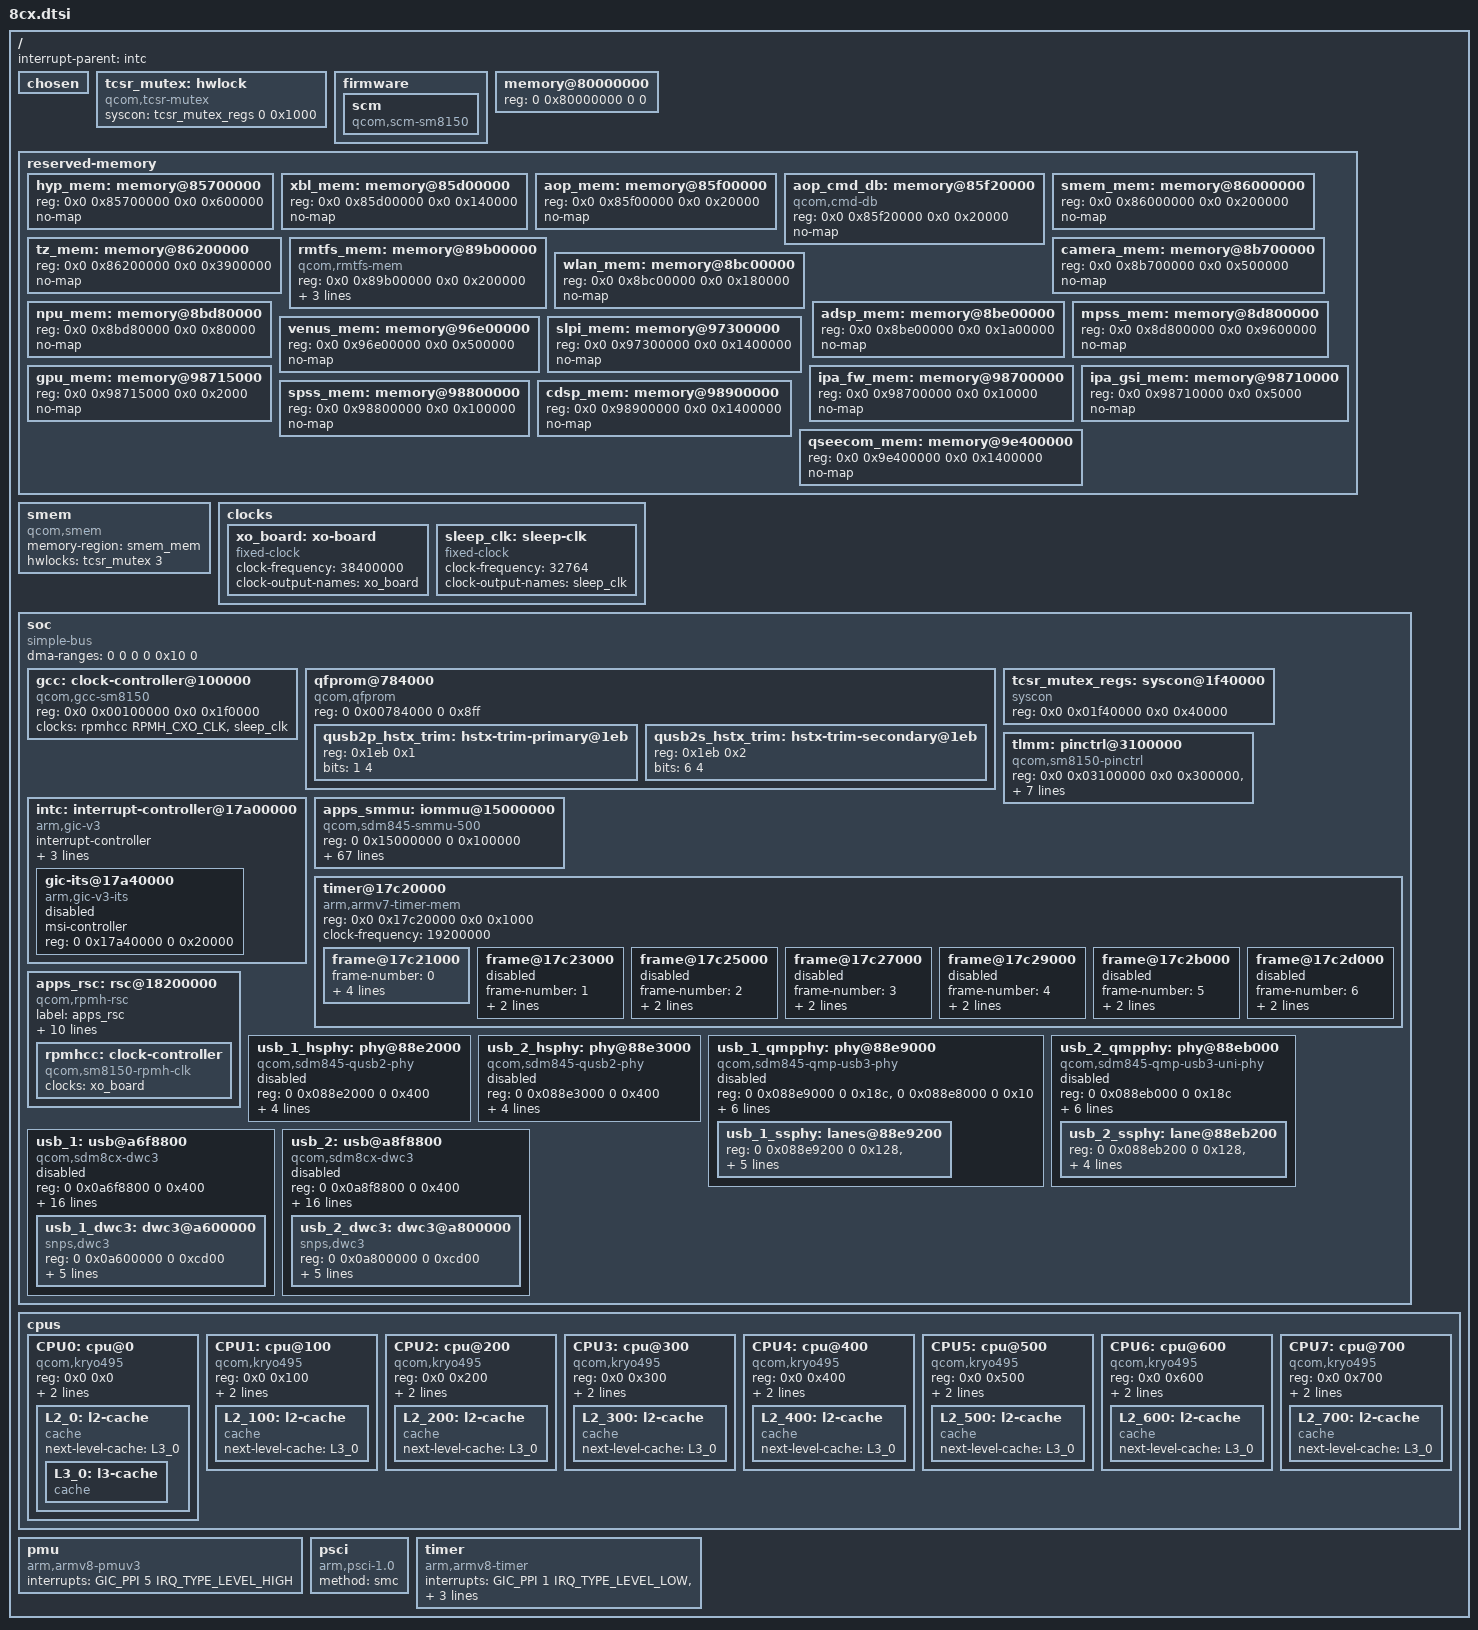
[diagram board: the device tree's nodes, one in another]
// SPDX-License-Identifier: BSD-3-Clause

#include <dt-bindings/clock/qcom,gcc-sdm845.h>
#include <dt-bindings/interrupt-controller/arm-gic.h>
#include <dt-bindings/phy/phy-qcom-qusb2.h>
#include <dt-bindings/soc/qcom,rpmh-rsc.h>
#include <dt-bindings/clock/qcom,rpmh.h>

/ {
	interrupt-parent = <&intc>;

	#address-cells = <2>;
	#size-cells = <2>;

	chosen { };

	tcsr_mutex: hwlock {
		compatible = "qcom,tcsr-mutex";
		syscon = <&tcsr_mutex_regs 0 0x1000>;
		#hwlock-cells = <1>;
	};

	firmware {
		scm: scm {
			compatible = "qcom,scm-sm8150", "qcom,scm";
			#reset-cells = <1>;
		};
	};

	memory@80000000 {
		device_type = "memory";
		/* We expect the bootloader to fill in the size */
		reg = <0 0x80000000 0 0>;
	};

	reserved-memory {
		#address-cells = <2>;
		#size-cells = <2>;
		ranges;

		hyp_mem: memory@85700000 {
			reg = <0x0 0x85700000 0x0 0x600000>;
			no-map;
		};

		xbl_mem: memory@85d00000 {
			reg = <0x0 0x85d00000 0x0 0x140000>;
			no-map;
		};

		aop_mem: memory@85f00000 {
			reg = <0x0 0x85f00000 0x0 0x20000>;
			no-map;
		};

		aop_cmd_db: memory@85f20000 {
			compatible = "qcom,cmd-db";
			reg = <0x0 0x85f20000 0x0 0x20000>;
			no-map;
		};

		smem_mem: memory@86000000 {
			reg = <0x0 0x86000000 0x0 0x200000>;
			no-map;
		};

		tz_mem: memory@86200000 {
			reg = <0x0 0x86200000 0x0 0x3900000>;
			no-map;
		};

		rmtfs_mem: memory@89b00000 {
			compatible = "qcom,rmtfs-mem";
			reg = <0x0 0x89b00000 0x0 0x200000>;
			no-map;

			qcom,client-id = <1>;
			qcom,vmid = <15>;
		};

		camera_mem: memory@8b700000 {
			reg = <0x0 0x8b700000 0x0 0x500000>;
			no-map;
		};

		wlan_mem: memory@8bc00000 {
			reg = <0x0 0x8bc00000 0x0 0x180000>;
			no-map;
		};

		npu_mem: memory@8bd80000 {
			reg = <0x0 0x8bd80000 0x0 0x80000>;
			no-map;
		};

		adsp_mem: memory@8be00000 {
			reg = <0x0 0x8be00000 0x0 0x1a00000>;
			no-map;
		};

		mpss_mem: memory@8d800000 {
			reg = <0x0 0x8d800000 0x0 0x9600000>;
			no-map;
		};

		venus_mem: memory@96e00000 {
			reg = <0x0 0x96e00000 0x0 0x500000>;
			no-map;
		};

		slpi_mem: memory@97300000 {
			reg = <0x0 0x97300000 0x0 0x1400000>;
			no-map;
		};

		ipa_fw_mem: memory@98700000 {
			reg = <0x0 0x98700000 0x0 0x10000>;
			no-map;
		};

		ipa_gsi_mem: memory@98710000 {
			reg = <0x0 0x98710000 0x0 0x5000>;
			no-map;
		};

		gpu_mem: memory@98715000 {
			reg = <0x0 0x98715000 0x0 0x2000>;
			no-map;
		};

		spss_mem: memory@98800000 {
			reg = <0x0 0x98800000 0x0 0x100000>;
			no-map;
		};

		cdsp_mem: memory@98900000 {
			reg = <0x0 0x98900000 0x0 0x1400000>;
			no-map;
		};

		qseecom_mem: memory@9e400000 {
			reg = <0x0 0x9e400000 0x0 0x1400000>;
			no-map;
		};
	};

	smem {
		compatible = "qcom,smem";
		memory-region = <&smem_mem>;
		hwlocks = <&tcsr_mutex 3>;
	};


	clocks {
		xo_board: xo-board {
			compatible = "fixed-clock";
			#clock-cells = <0>;
			clock-frequency = <38400000>;
			clock-output-names = "xo_board";
		};

		sleep_clk: sleep-clk {
			compatible = "fixed-clock";
			#clock-cells = <0>;
			clock-frequency = <32764>;
			clock-output-names = "sleep_clk";
		};
	};

	soc: soc {
		#address-cells = <2>;
		#size-cells = <2>;
		ranges = <0 0 0 0 0x10 0>;
		dma-ranges = <0 0 0 0 0x10 0>;
		compatible = "simple-bus";

		gcc: clock-controller@100000 {
			compatible = "qcom,gcc-sm8150";
			reg = <0x0 0x00100000 0x0 0x1f0000>;
			#clock-cells = <1>;
			#reset-cells = <1>;
			#power-domain-cells = <1>;
			clock-names = "bi_tcxo",
				      "sleep_clk";
			clocks = <&rpmhcc RPMH_CXO_CLK>,
				 <&sleep_clk>;
		};

		qfprom@784000 {
			compatible = "qcom,qfprom";
			reg = <0 0x00784000 0 0x8ff>;
			#address-cells = <1>;
			#size-cells = <1>;

			qusb2p_hstx_trim: hstx-trim-primary@1eb {
				reg = <0x1eb 0x1>;
				bits = <1 4>;
			};

			qusb2s_hstx_trim: hstx-trim-secondary@1eb {
				reg = <0x1eb 0x2>;
				bits = <6 4>;
			};
		};


		tcsr_mutex_regs: syscon@1f40000 {
			compatible = "syscon";
			reg = <0x0 0x01f40000 0x0 0x40000>;
		};

		tlmm: pinctrl@3100000 {
			compatible = "qcom,sm8150-pinctrl";
			reg = <0x0 0x03100000 0x0 0x300000>,
			      <0x0 0x03500000 0x0 0x300000>,
			      <0x0 0x03900000 0x0 0x300000>,
			      <0x0 0x03D00000 0x0 0x300000>;
			reg-names = "west", "east", "north", "south";
			interrupts = <GIC_SPI 208 IRQ_TYPE_LEVEL_HIGH>;
			gpio-ranges = <&tlmm 0 0 175>;
			gpio-controller;
			#gpio-cells = <2>;
			interrupt-controller;
			#interrupt-cells = <2>;
		};

		intc: interrupt-controller@17a00000 {
			compatible = "arm,gic-v3";
			#address-cells = <2>;
			#size-cells = <2>;
			ranges;
			#interrupt-cells = <3>;
			interrupt-controller;
			reg = <0 0x17a00000 0 0x10000>,     /* GICD */
			      <0 0x17a60000 0 0x100000>;    /* GICR * 8 */
			interrupts = <GIC_PPI 9 IRQ_TYPE_LEVEL_HIGH>;

			gic-its@17a40000 {
				compatible = "arm,gic-v3-its";
				msi-controller;
				#msi-cells = <1>;
				reg = <0 0x17a40000 0 0x20000>;
				status = "disabled";
			};
		};

		apps_smmu: iommu@15000000 {
			compatible = "qcom,sdm845-smmu-500", "arm,mmu-500";
			reg = <0 0x15000000 0 0x100000>;
			#iommu-cells = <2>;
			#global-interrupts = <1>;
			interrupts = <GIC_SPI 65 IRQ_TYPE_LEVEL_HIGH>,
				     <GIC_SPI 96 IRQ_TYPE_LEVEL_HIGH>,
				     <GIC_SPI 97 IRQ_TYPE_LEVEL_HIGH>,
				     <GIC_SPI 98 IRQ_TYPE_LEVEL_HIGH>,
				     <GIC_SPI 99 IRQ_TYPE_LEVEL_HIGH>,
				     <GIC_SPI 100 IRQ_TYPE_LEVEL_HIGH>,
				     <GIC_SPI 101 IRQ_TYPE_LEVEL_HIGH>,
				     <GIC_SPI 102 IRQ_TYPE_LEVEL_HIGH>,
				     <GIC_SPI 103 IRQ_TYPE_LEVEL_HIGH>,
				     <GIC_SPI 104 IRQ_TYPE_LEVEL_HIGH>,
				     <GIC_SPI 105 IRQ_TYPE_LEVEL_HIGH>,
				     <GIC_SPI 106 IRQ_TYPE_LEVEL_HIGH>,
				     <GIC_SPI 107 IRQ_TYPE_LEVEL_HIGH>,
				     <GIC_SPI 108 IRQ_TYPE_LEVEL_HIGH>,
				     <GIC_SPI 109 IRQ_TYPE_LEVEL_HIGH>,
				     <GIC_SPI 110 IRQ_TYPE_LEVEL_HIGH>,
				     <GIC_SPI 111 IRQ_TYPE_LEVEL_HIGH>,
				     <GIC_SPI 112 IRQ_TYPE_LEVEL_HIGH>,
				     <GIC_SPI 113 IRQ_TYPE_LEVEL_HIGH>,
				     <GIC_SPI 114 IRQ_TYPE_LEVEL_HIGH>,
				     <GIC_SPI 115 IRQ_TYPE_LEVEL_HIGH>,
				     <GIC_SPI 116 IRQ_TYPE_LEVEL_HIGH>,
				     <GIC_SPI 117 IRQ_TYPE_LEVEL_HIGH>,
				     <GIC_SPI 118 IRQ_TYPE_LEVEL_HIGH>,
				     <GIC_SPI 181 IRQ_TYPE_LEVEL_HIGH>,
				     <GIC_SPI 182 IRQ_TYPE_LEVEL_HIGH>,
				     <GIC_SPI 183 IRQ_TYPE_LEVEL_HIGH>,
				     <GIC_SPI 184 IRQ_TYPE_LEVEL_HIGH>,
				     <GIC_SPI 185 IRQ_TYPE_LEVEL_HIGH>,
				     <GIC_SPI 186 IRQ_TYPE_LEVEL_HIGH>,
				     <GIC_SPI 187 IRQ_TYPE_LEVEL_HIGH>,
				     <GIC_SPI 188 IRQ_TYPE_LEVEL_HIGH>,
				     <GIC_SPI 189 IRQ_TYPE_LEVEL_HIGH>,
				     <GIC_SPI 190 IRQ_TYPE_LEVEL_HIGH>,
				     <GIC_SPI 191 IRQ_TYPE_LEVEL_HIGH>,
				     <GIC_SPI 192 IRQ_TYPE_LEVEL_HIGH>,
				     <GIC_SPI 315 IRQ_TYPE_LEVEL_HIGH>,
				     <GIC_SPI 316 IRQ_TYPE_LEVEL_HIGH>,
				     <GIC_SPI 317 IRQ_TYPE_LEVEL_HIGH>,
				     <GIC_SPI 318 IRQ_TYPE_LEVEL_HIGH>,
				     <GIC_SPI 319 IRQ_TYPE_LEVEL_HIGH>,
				     <GIC_SPI 320 IRQ_TYPE_LEVEL_HIGH>,
				     <GIC_SPI 321 IRQ_TYPE_LEVEL_HIGH>,
				     <GIC_SPI 322 IRQ_TYPE_LEVEL_HIGH>,
				     <GIC_SPI 323 IRQ_TYPE_LEVEL_HIGH>,
				     <GIC_SPI 324 IRQ_TYPE_LEVEL_HIGH>,
				     <GIC_SPI 325 IRQ_TYPE_LEVEL_HIGH>,
				     <GIC_SPI 326 IRQ_TYPE_LEVEL_HIGH>,
				     <GIC_SPI 327 IRQ_TYPE_LEVEL_HIGH>,
				     <GIC_SPI 328 IRQ_TYPE_LEVEL_HIGH>,
				     <GIC_SPI 329 IRQ_TYPE_LEVEL_HIGH>,
				     <GIC_SPI 330 IRQ_TYPE_LEVEL_HIGH>,
				     <GIC_SPI 331 IRQ_TYPE_LEVEL_HIGH>,
				     <GIC_SPI 332 IRQ_TYPE_LEVEL_HIGH>,
				     <GIC_SPI 333 IRQ_TYPE_LEVEL_HIGH>,
				     <GIC_SPI 334 IRQ_TYPE_LEVEL_HIGH>,
				     <GIC_SPI 335 IRQ_TYPE_LEVEL_HIGH>,
				     <GIC_SPI 336 IRQ_TYPE_LEVEL_HIGH>,
				     <GIC_SPI 337 IRQ_TYPE_LEVEL_HIGH>,
				     <GIC_SPI 338 IRQ_TYPE_LEVEL_HIGH>,
				     <GIC_SPI 339 IRQ_TYPE_LEVEL_HIGH>,
				     <GIC_SPI 340 IRQ_TYPE_LEVEL_HIGH>,
				     <GIC_SPI 341 IRQ_TYPE_LEVEL_HIGH>,
				     <GIC_SPI 342 IRQ_TYPE_LEVEL_HIGH>,
				     <GIC_SPI 343 IRQ_TYPE_LEVEL_HIGH>;

			qcom,smmu-500-fw-impl-errata;
		};

		timer@17c20000 {
			#address-cells = <2>;
			#size-cells = <2>;
			ranges;
			compatible = "arm,armv7-timer-mem";
			reg = <0x0 0x17c20000 0x0 0x1000>;
			clock-frequency = <19200000>;

			frame@17c21000{
				frame-number = <0>;
				interrupts = <GIC_SPI 8 IRQ_TYPE_LEVEL_HIGH>,
					     <GIC_SPI 6 IRQ_TYPE_LEVEL_HIGH>;
				reg = <0x0 0x17c21000 0x0 0x1000>,
				      <0x0 0x17c22000 0x0 0x1000>;
			};

			frame@17c23000 {
				frame-number = <1>;
				interrupts = <GIC_SPI 9 IRQ_TYPE_LEVEL_HIGH>;
				reg = <0x0 0x17c23000 0x0 0x1000>;
				status = "disabled";
			};

			frame@17c25000 {
				frame-number = <2>;
				interrupts = <GIC_SPI 10 IRQ_TYPE_LEVEL_HIGH>;
				reg = <0x0 0x17c25000 0x0 0x1000>;
				status = "disabled";
			};

			frame@17c27000 {
				frame-number = <3>;
				interrupts = <GIC_SPI 11 IRQ_TYPE_LEVEL_HIGH>;
				reg = <0x0 0x17c26000 0x0 0x1000>;
				status = "disabled";
			};

			frame@17c29000 {
				frame-number = <4>;
				interrupts = <GIC_SPI 12 IRQ_TYPE_LEVEL_HIGH>;
				reg = <0x0 0x17c29000 0x0 0x1000>;
				status = "disabled";
			};

			frame@17c2b000 {
				frame-number = <5>;
				interrupts = <GIC_SPI 13 IRQ_TYPE_LEVEL_HIGH>;
				reg = <0x0 0x17c2b000 0x0 0x1000>;
				status = "disabled";
			};

			frame@17c2d000 {
				frame-number = <6>;
				interrupts = <GIC_SPI 14 IRQ_TYPE_LEVEL_HIGH>;
				reg = <0x0 0x17c2d000 0x0 0x1000>;
				status = "disabled";
			};
		};

		apps_rsc: rsc@18200000 {
			label = "apps_rsc";
			compatible = "qcom,rpmh-rsc";
			reg = <0x0 0x18200000 0x0 0x10000>,
			      <0x0 0x18210000 0x0 0x10000>,
			      <0x0 0x18220000 0x0 0x10000>;
			reg-names = "drv-0", "drv-1", "drv-2";
			interrupts = <GIC_SPI 3 IRQ_TYPE_LEVEL_HIGH>,
				     <GIC_SPI 4 IRQ_TYPE_LEVEL_HIGH>,
				     <GIC_SPI 5 IRQ_TYPE_LEVEL_HIGH>;
			qcom,tcs-offset = <0xd00>;
			qcom,drv-id = <2>;
			qcom,tcs-config = <ACTIVE_TCS  2>,
					  <SLEEP_TCS   1>,
					  <WAKE_TCS    1>,
					  <CONTROL_TCS 0>;

			rpmhcc: clock-controller {
				compatible = "qcom,sm8150-rpmh-clk";
				#clock-cells = <1>;
				clock-names = "xo";
				clocks = <&xo_board>;
			};
		};

		usb_1_hsphy: phy@88e2000 {
			compatible = "qcom,sdm845-qusb2-phy";
			reg = <0 0x088e2000 0 0x400>;
			status = "disabled";
			#phy-cells = <0>;

			clocks = <&gcc GCC_USB_PHY_CFG_AHB2PHY_CLK>,
				 <&rpmhcc RPMH_CXO_CLK>;
			clock-names = "cfg_ahb", "ref";

			resets = <&gcc GCC_QUSB2PHY_PRIM_BCR>;

			nvmem-cells = <&qusb2p_hstx_trim>;
		};

		usb_2_hsphy: phy@88e3000 {
			compatible = "qcom,sdm845-qusb2-phy";
			reg = <0 0x088e3000 0 0x400>;
			status = "disabled";
			#phy-cells = <0>;

			clocks = <&gcc GCC_USB_PHY_CFG_AHB2PHY_CLK>,
				 <&rpmhcc RPMH_CXO_CLK>;
			clock-names = "cfg_ahb", "ref";

			resets = <&gcc GCC_QUSB2PHY_SEC_BCR>;

			nvmem-cells = <&qusb2s_hstx_trim>;
		};

		usb_1_qmpphy: phy@88e9000 {
			compatible = "qcom,sdm845-qmp-usb3-phy";
			reg = <0 0x088e9000 0 0x18c>,
			      <0 0x088e8000 0 0x10>;
			reg-names = "reg-base", "dp_com";
			status = "disabled";
			#clock-cells = <1>;
			#address-cells = <2>;
			#size-cells = <2>;
			ranges;

			clocks = <&gcc GCC_USB3_PRIM_PHY_AUX_CLK>,
				 <&gcc GCC_USB_PHY_CFG_AHB2PHY_CLK>,
				 <&gcc GCC_USB3_PRIM_CLKREF_CLK>,
				 <&gcc GCC_USB3_PRIM_PHY_COM_AUX_CLK>;
			clock-names = "aux", "cfg_ahb", "ref", "com_aux";

			resets = <&gcc GCC_USB3_DP_PHY_PRIM_BCR>,
				 <&gcc GCC_USB3_PHY_PRIM_BCR>;
			reset-names = "phy", "common";

			usb_1_ssphy: lanes@88e9200 {
				reg = <0 0x088e9200 0 0x128>,
				      <0 0x088e9400 0 0x200>,
				      <0 0x088e9c00 0 0x218>,
				      <0 0x088e9600 0 0x128>,
				      <0 0x088e9800 0 0x200>,
				      <0 0x088e9a00 0 0x100>;
				#phy-cells = <0>;
				clocks = <&gcc GCC_USB3_PRIM_PHY_PIPE_CLK>;
				clock-names = "pipe0";
				clock-output-names = "usb3_phy_pipe_clk_src";
			};
		};

		usb_2_qmpphy: phy@88eb000 {
			compatible = "qcom,sdm845-qmp-usb3-uni-phy";
			reg = <0 0x088eb000 0 0x18c>;
			status = "disabled";
			#clock-cells = <1>;
			#address-cells = <2>;
			#size-cells = <2>;
			ranges;

			clocks = <&gcc GCC_USB3_SEC_PHY_AUX_CLK>,
				 <&gcc GCC_USB_PHY_CFG_AHB2PHY_CLK>,
				 <&gcc GCC_USB3_SEC_CLKREF_CLK>,
				 <&gcc GCC_USB3_SEC_PHY_COM_AUX_CLK>;
			clock-names = "aux", "cfg_ahb", "ref", "com_aux";

			resets = <&gcc GCC_USB3PHY_PHY_SEC_BCR>,
				 <&gcc GCC_USB3_PHY_SEC_BCR>;
			reset-names = "phy", "common";

			usb_2_ssphy: lane@88eb200 {
				reg = <0 0x088eb200 0 0x128>,
				      <0 0x088eb400 0 0x1fc>,
				      <0 0x088eb800 0 0x218>,
				      <0 0x088eb600 0 0x70>;
				#phy-cells = <0>;
				clocks = <&gcc GCC_USB3_SEC_PHY_PIPE_CLK>;
				clock-names = "pipe0";
				clock-output-names = "usb3_uni_phy_pipe_clk_src";
			};
		};

		usb_1: usb@a6f8800 {
			compatible = "qcom,sdm8cx-dwc3", "qcom,dwc3";
			reg = <0 0x0a6f8800 0 0x400>;
			status = "disabled";
			#address-cells = <2>;
			#size-cells = <2>;
			ranges;
			dma-ranges;

			clocks = <&gcc GCC_CFG_NOC_USB3_PRIM_AXI_CLK>,
				 <&gcc GCC_USB30_PRIM_MASTER_CLK>,
				 <&gcc GCC_AGGRE_USB3_PRIM_AXI_CLK>,
				 <&gcc GCC_USB30_PRIM_MOCK_UTMI_CLK>,
				 <&gcc GCC_USB30_PRIM_SLEEP_CLK>;
			clock-names = "cfg_noc", "core", "iface", "mock_utmi",
				      "sleep";

			assigned-clocks = <&gcc GCC_USB30_PRIM_MOCK_UTMI_CLK>,
					  <&gcc GCC_USB30_PRIM_MASTER_CLK>;
			assigned-clock-rates = <19200000>, <150000000>;

			interrupts = <GIC_SPI 131 IRQ_TYPE_LEVEL_HIGH>,
				     <GIC_SPI 486 IRQ_TYPE_LEVEL_HIGH>,
				     <GIC_SPI 488 IRQ_TYPE_LEVEL_HIGH>,
				     <GIC_SPI 489 IRQ_TYPE_LEVEL_HIGH>;
			interrupt-names = "hs_phy_irq", "ss_phy_irq",
					  "dm_hs_phy_irq", "dp_hs_phy_irq";

			power-domains = <&gcc USB30_PRIM_GDSC>;

			resets = <&gcc GCC_USB30_PRIM_BCR>;

			usb_1_dwc3: dwc3@a600000 {
				compatible = "snps,dwc3";
				reg = <0 0x0a600000 0 0xcd00>;
				interrupts = <GIC_SPI 133 IRQ_TYPE_LEVEL_HIGH>;
				iommus = <&apps_smmu 0x740 0>;
				snps,dis_u2_susphy_quirk;
				snps,dis_enblslpm_quirk;
				phys = <&usb_1_hsphy>, <&usb_1_ssphy>;
				phy-names = "usb2-phy", "usb3-phy";
			};
		};

		usb_2: usb@a8f8800 {
			compatible = "qcom,sdm8cx-dwc3", "qcom,dwc3";
			reg = <0 0x0a8f8800 0 0x400>;
			status = "disabled";
			#address-cells = <2>;
			#size-cells = <2>;
			ranges;
			dma-ranges;

			clocks = <&gcc GCC_CFG_NOC_USB3_SEC_AXI_CLK>,
				 <&gcc GCC_USB30_SEC_MASTER_CLK>,
				 <&gcc GCC_AGGRE_USB3_SEC_AXI_CLK>,
				 <&gcc GCC_USB30_SEC_MOCK_UTMI_CLK>,
				 <&gcc GCC_USB30_SEC_SLEEP_CLK>;
			clock-names = "cfg_noc", "core", "iface", "mock_utmi",
				      "sleep";

			assigned-clocks = <&gcc GCC_USB30_SEC_MOCK_UTMI_CLK>,
					  <&gcc GCC_USB30_SEC_MASTER_CLK>;
			assigned-clock-rates = <19200000>, <150000000>;

			interrupts = <GIC_SPI 136 IRQ_TYPE_LEVEL_HIGH>,
				     <GIC_SPI 487 IRQ_TYPE_LEVEL_HIGH>,
				     <GIC_SPI 490 IRQ_TYPE_LEVEL_HIGH>,
				     <GIC_SPI 491 IRQ_TYPE_LEVEL_HIGH>;
			interrupt-names = "hs_phy_irq", "ss_phy_irq",
					  "dm_hs_phy_irq", "dp_hs_phy_irq";

			power-domains = <&gcc USB30_SEC_GDSC>;

			resets = <&gcc GCC_USB30_SEC_BCR>;

			usb_2_dwc3: dwc3@a800000 {
				compatible = "snps,dwc3";
				reg = <0 0x0a800000 0 0xcd00>;
				interrupts = <GIC_SPI 138 IRQ_TYPE_LEVEL_HIGH>;
				iommus = <&apps_smmu 0x760 0>;
				snps,dis_u2_susphy_quirk;
				snps,dis_enblslpm_quirk;
				phys = <&usb_2_hsphy>, <&usb_2_ssphy>;
				phy-names = "usb2-phy", "usb3-phy";
			};
		};



	};

	cpus {
		#address-cells = <2>;
		#size-cells = <0>;

		CPU0: cpu@0 {
			device_type = "cpu";
			compatible = "qcom,kryo495";
			reg = <0x0 0x0>;
			enable-method = "psci";
			next-level-cache = <&L2_0>;
			L2_0: l2-cache {
				compatible = "cache";
				next-level-cache = <&L3_0>;
				L3_0: l3-cache {
				      compatible = "cache";
				};
			};
		};

		CPU1: cpu@100 {
			device_type = "cpu";
			compatible = "qcom,kryo495";
			reg = <0x0 0x100>;
			enable-method = "psci";
			next-level-cache = <&L2_100>;
			L2_100: l2-cache {
				compatible = "cache";
				next-level-cache = <&L3_0>;
			};

		};

		CPU2: cpu@200 {
			device_type = "cpu";
			compatible = "qcom,kryo495";
			reg = <0x0 0x200>;
			enable-method = "psci";
			next-level-cache = <&L2_200>;
			L2_200: l2-cache {
				compatible = "cache";
				next-level-cache = <&L3_0>;
			};
		};

		CPU3: cpu@300 {
			device_type = "cpu";
			compatible = "qcom,kryo495";
			reg = <0x0 0x300>;
			enable-method = "psci";
			next-level-cache = <&L2_300>;
			L2_300: l2-cache {
				compatible = "cache";
				next-level-cache = <&L3_0>;
			};
		};

		CPU4: cpu@400 {
			device_type = "cpu";
			compatible = "qcom,kryo495";
			reg = <0x0 0x400>;
			enable-method = "psci";
			next-level-cache = <&L2_400>;
			L2_400: l2-cache {
				compatible = "cache";
				next-level-cache = <&L3_0>;
			};
		};

		CPU5: cpu@500 {
			device_type = "cpu";
			compatible = "qcom,kryo495";
			reg = <0x0 0x500>;
			enable-method = "psci";
			next-level-cache = <&L2_500>;
			L2_500: l2-cache {
				compatible = "cache";
				next-level-cache = <&L3_0>;
			};
		};

		CPU6: cpu@600 {
			device_type = "cpu";
			compatible = "qcom,kryo495";
			reg = <0x0 0x600>;
			enable-method = "psci";
			next-level-cache = <&L2_600>;
			L2_600: l2-cache {
				compatible = "cache";
				next-level-cache = <&L3_0>;
			};
		};

		CPU7: cpu@700 {
			device_type = "cpu";
			compatible = "qcom,kryo495";
			reg = <0x0 0x700>;
			enable-method = "psci";
			next-level-cache = <&L2_700>;
			L2_700: l2-cache {
				compatible = "cache";
				next-level-cache = <&L3_0>;
			};
		};
	};


	pmu {
		compatible = "arm,armv8-pmuv3";
		interrupts = <GIC_PPI 5 IRQ_TYPE_LEVEL_HIGH>;
	};

	psci {
		compatible = "arm,psci-1.0";
		method = "smc";
	};

	timer {
		compatible = "arm,armv8-timer";
		interrupts = <GIC_PPI 1 IRQ_TYPE_LEVEL_LOW>,
			     <GIC_PPI 2 IRQ_TYPE_LEVEL_LOW>,
			     <GIC_PPI 3 IRQ_TYPE_LEVEL_LOW>,
			     <GIC_PPI 0 IRQ_TYPE_LEVEL_LOW>;
	};
};
